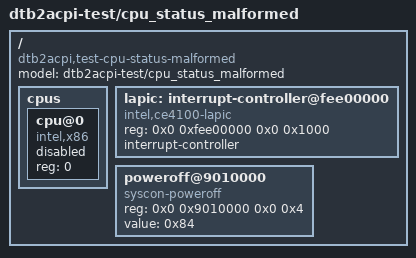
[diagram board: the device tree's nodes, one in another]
/dts-v1/;

/* `status = "bogus"` — not one of the DT-spec values
 * ("okay" | "disabled" | "fail" | "fail-<sss>" | "reserved").
 * decode_cpu_status must reject with MalformedProperty.
 */

/ {
	#address-cells = <2>;
	#size-cells = <2>;
	model = "dtb2acpi-test/cpu_status_malformed";
	compatible = "dtb2acpi,test-cpu-status-malformed";

	cpus {
		#address-cells = <1>;
		#size-cells = <0>;

		cpu@0 {
			device_type = "cpu";
			reg = <0>;
			compatible = "intel,x86";
			status = "bogus";
		};
	};

		lapic: interrupt-controller@fee00000 {
		compatible = "intel,ce4100-lapic";
		reg = <0x0 0xfee00000 0x0 0x1000>;
		interrupt-controller;
		#interrupt-cells = <2>;
	};
		poweroff@9010000 {
		compatible = "syscon-poweroff";
		reg = <0x0 0x9010000 0x0 0x4>;
		value = <0x84>;
	};
};
